VERSION ""

NS_ :

BS_:

BU_:

BO_ 1026 TPMS: 8 Vector__XXX

BO_ 771 IMU: 4 Vector__XXX
 SG_ Yaw : 0|8@1- (10,0) [-1280|1270] "degrees/s" Vector__XXX
 SG_ LateralAccel : 24|8@1- (0.0313,0) [-4.0064|3.9751] "g" Vector__XXX

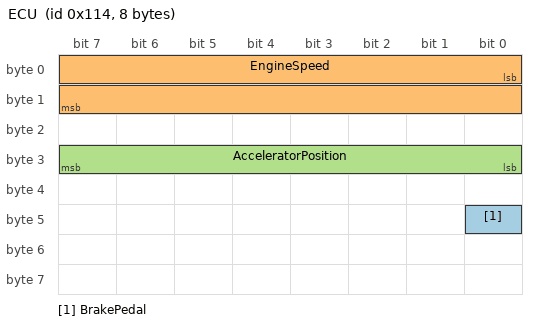
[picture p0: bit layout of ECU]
BO_ 276 ECU: 8 Vector__XXX
 SG_ BrakePedal : 40|1@1+ (100,0) [0|100] "position" Vector__XXX
 SG_ EngineSpeed : 0|16@1+ (0.25,0) [0|16383.75] "RPM" Vector__XXX
 SG_ AcceleratorPosition : 24|8@1+ (0.3984,0) [0|101.592] "%" Vector__XXX

BO_ 2147483781 SteeringAngle: 8 Vector__XXX
 SG_ SteeringAngle : 0|16@1- (0.05,0) [-1638.4|1638.35] "degrees" Vector__XXX

BA_DEF_ SG_  "SigType" ENUM  "Default","Range","RangeSigned","ASCII","Discrete","Control","ReferencePGN","DTC","StringDelimiter","StringLength","StringLengthControl","MessageCounter","MessageChecksum";
BA_DEF_ SG_  "GenSigEVName" STRING ;
BA_DEF_ SG_  "GenSigILSupport" ENUM  "No","Yes";
BA_DEF_ SG_  "GenSigSendType" ENUM  "Cyclic","OnWrite","OnWriteWithRepetition","OnChange","OnChangeWithRepetition","IfActive","IfActiveWithRepetition","NoSigSendType";
BA_DEF_ BO_  "GenMsgILSupport" ENUM  "No","Yes";
BA_DEF_ BU_  "NmStationAddress" INT 0 255;
BA_DEF_ BO_  "GenMsgSendType" ENUM  "cyclic","NotUsed","IfActive","NotUsed","NotUsed","NotUsed","NotUsed","NotUsed","noMsgSendType";
BA_DEF_ BO_  "GenMsgRequestable" INT 0 1;
BA_DEF_  "DBName" STRING ;
BA_DEF_  "BusType" STRING ;
BA_DEF_  "ProtocolType" STRING ;
BA_DEF_ BO_  "VFrameFormat" ENUM  "StandardCAN","ExtendedCAN","reserved","J1939PG";
BA_DEF_DEF_  "SigType" "Default";
BA_DEF_DEF_  "GenSigEVName" "Env@Nodename_@Signame";
BA_DEF_DEF_  "GenSigILSupport" "Yes";
BA_DEF_DEF_  "GenSigSendType" "NoSigSendType";
BA_DEF_DEF_  "GenMsgILSupport" "Yes";
BA_DEF_DEF_  "NmStationAddress" 254;
BA_DEF_DEF_  "GenMsgSendType" "noMsgSendType";
BA_DEF_DEF_  "GenMsgRequestable" 1;
BA_DEF_DEF_  "DBName" "";
BA_DEF_DEF_  "BusType" "CAN";
BA_DEF_DEF_  "ProtocolType" "J1939";
BA_DEF_DEF_  "VFrameFormat" "J1939PG";
BA_ "DBName" "evora";
BA_ "VFrameFormat" BO_ 1026 0;
BA_ "VFrameFormat" BO_ 771 0;
BA_ "VFrameFormat" BO_ 276 0;
